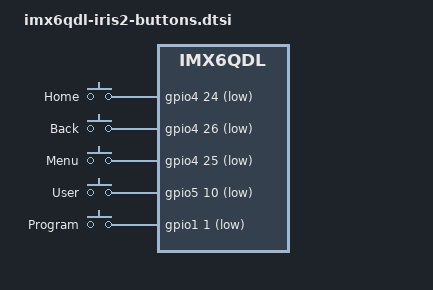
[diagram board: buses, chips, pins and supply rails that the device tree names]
/*
 * Copyright (C) 2015-2017 Variscite Ltd.
 * Copyright (C) 2018-2019 Oak Ridge National Laboratory
 *
 * This program is free software; you can redistribute it and/or modify
 * it under the terms of the GNU General Public License version 2 as
 * published by the Free Software Foundation.
 *
 * GPIOs for IRIS2 - default defined as inputs able to wakeup the CPU
 */
/ {
	gpio-keys {
		compatible = "gpio-keys";

		/* J2.6 GPIO_3 */
		home {
			label = "Home";
			gpios = <&gpio4 24 1>;
			linux,code = <KEY_HOMEPAGE>;
			gpio-key,wakeup;
		};

		/* J2.4 GPIO_5 */
		back {
			label = "Back";
			gpios = <&gpio4 26 1>;
			linux,code = <KEY_BACK>;
			gpio-key,wakeup;
		};

		/* J2.5 GPIO_4 */
		menu {
			label = "Menu";
			gpios = <&gpio4 25 1>;
			linux,code = <KEY_MENU>;
			gpio-key,wakeup;
		};

		/* J2.7 GPIO_2 */
		user {
			label = "User";
			gpios = <&gpio5 10 1>;
			linux,code = <BTN_MISC>;
			gpio-key,wakeup;
		};

		/* J3.3 GPIO_1 */
		program {
			label = "Program";
			gpios = <&gpio1 1 1>;
			linux,code = <KEY_PROGRAM>;
			gpio-key,wakeup;
		};
	};
};

